# R7FA4W1AD register map
Vendor: Renesas; Series: RA4; File version: 1.0
CPU: CM4 r0p1, little endian, MPU, FPU, VTOR, 4 interrupt priority bits
Registers are 8-bit, read-write, reset 0x0 unless marked. A register's access mark holds for its fields unless they carry their own. Offsets are from the block's base; [hi:lo] are bit positions; {n}, {i} and the like mark numbered series; 'fields as' and 'values as' point back to an identical list.

## PMISC — Miscellaneous Port Control Register
Base 0x40040D00
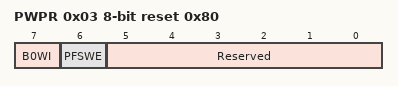
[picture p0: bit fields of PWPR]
0x03 PWPR reset 0x80 — Write-Protect Register
  [7] B0WI — PFSWE Bit Write Disable
    0=Writing to the PFSWE bit is enabled; 1=Writing to the PFSWE bit is disabled
  [6] PFSWE — PFS Register Write Enable
    0=Writing to the PFS register is disabled; 1=Writing to the PFS register is enabled
  [5:0] Reserved — These bits are read as 000000. The write value should be 000000.

## ELC — Event Link Controller
Base 0x40041000
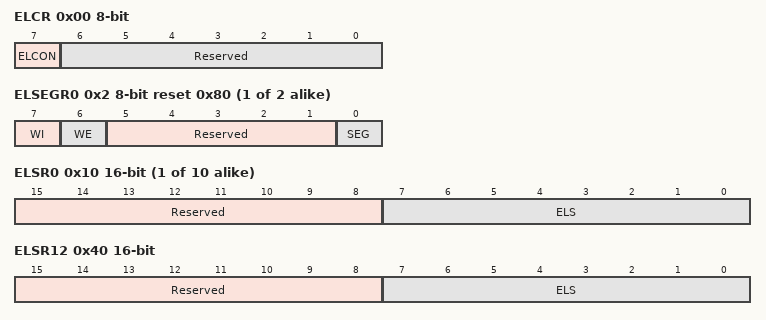
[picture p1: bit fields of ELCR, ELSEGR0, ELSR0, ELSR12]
0x00 ELCR — Event Link Controller Register
  [7] ELCON — All Event Link Enable
    0=ELC function is disabled; 1=ELC function is enabled
  [6:0] Reserved — These bits are read as 0000000. The write value should be 0000000.
{0x2+2i} ELSEGR{i} (i=0..1) reset 0x80 — Event Link Software Event Generation Register {i}
  [7] WI wo — ELSEGR Register Write Disable
    0=Write to ELSEGR register is enabled; 1=Write to ELSEGR register is disabled
  [6] WE — SEG Bit Write Enable
    0=Write to SEG bit is disabled; 1=Write to SEG bit is enabled
  [5:1] Reserved — These bits are read as 00000. The write value should be 00000.
  [0] SEG wo — Software Event Generation
    0=Normal operation; 1=Software event is generated
{0x10+4i} ELSR{i} (i=0..9) 16-bit — Event Link Setting Register {i}
  [15:8] Reserved — These bits are read as 00000000. The write value should be 00000000.
  [7:0] ELS — Event Link Select
    0=Event output to the corresponding peripheral module is disabled; other=others (Set the number for the event signal to be linked.)
0x40 ELSR12 16-bit — Event Link Setting Register 12
  fields as ELSR0
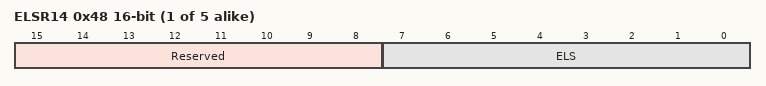
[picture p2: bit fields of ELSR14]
{0x10+4i} ELSR{i} (i=14..18) 16-bit — Event Link Setting Register {i}
  fields as ELSR0

## DOC — Data Operation Circuit
Base 0x40054100
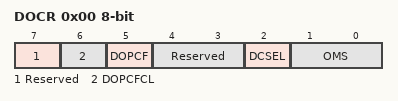
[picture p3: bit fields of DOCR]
0x00 DOCR — DOC Control Register
  [7] Reserved — This bit is read as 0. The write value should be 0.
  [6] DOPCFCL — DOPCF Clear
    0=Maintains the DOPCF flag state; 1=Clears the DOPCF flag
  [5] DOPCF ro — Data Operation Circuit FlagIndicates the result of an operation.
  [4:3] Reserved — These bits are read as 00. The write value should be 00.
  [2] DCSEL — Detection Condition Select
    0=DOPCF is set when data mismatch is detected; 1=DOPCF is set when data match is detected
  [1:0] OMS — Operating Mode Select
    0=Data comparison mode; 1=Data addition mode; 2=Data subtraction mode; 3=Setting prohibited
0x02 DODIR 16-bit — DOC Data Input Register
  [15:0] DODIR — 16-bit read-write register in which 16-bit data for use in the operations are stored.
0x04 DODSR 16-bit — DOC Data Setting Register
  [15:0] DODSR — This register stores 16-bit data for use as a reference in data comparison mode. This register also stores the results of operations in data addition and data subtraction modes.

## CRC — CRC Calculator
Base 0x40074000
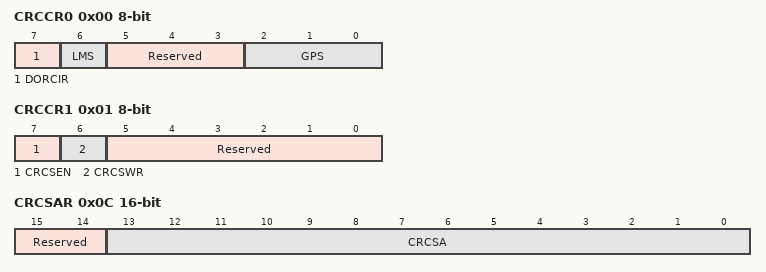
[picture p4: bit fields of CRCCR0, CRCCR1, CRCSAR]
0x00 CRCCR0 — CRC Control Register0
  [7] DORCIR wo — CRCDOR Register Clear
    0=No effect; 1=Clears the CRCDOR register
  [6] LMS — CRC Calculation Switching
    0=Generates CRC for LSB first communication; 1=Generates CRC for MSB first communication
  [5:3] Reserved — These bits are read as 000. The write value should be 000.
  [2:0] GPS — CRC Generating Polynomial Switching
    0=No calculation is executed; 1=8-bit CRC-8 (X8 + X2 + X + 1); 2=16-bit CRC-16 (X16 + X15 + X2 + 1); 3=16-bit CRC-CCITT (X16 + X12 + X5 + 1); 4=32-bit CRC-32 (X32+X26+X23+X22+X16+X12+X11+X10+X8+X7+X5+X4+X2+X+1); 5=32-bit CRC-32C (X32+X28+X27+X26+ X25+X23+X22+X20+X19+X18+X14+X13+X11+X10+X9+X8+X6+1); other=others (No calculation is executed.)
0x01 CRCCR1 — CRC Control Register1
  [7] CRCSEN — Snoop enable bit
    0=Disabled; 1=Enabled
  [6] CRCSWR — Snoop-on-write/read switch bit
    0=Snoop-on-read; 1=Snoop-on-write
  [5:0] Reserved — These bits are read as 000000. The write value should be 000000.
0x04 CRCDIR 32-bit — CRC Data Input Register
  [31:0] CRCDIR — Calculation input Data (Case of CRC-32, CRC-32C )
0x04 CRCDIR_BY (alternate view of CRCDIR) — CRC Data Input Register (byte access)
  [7:0] CRCDIR_BY — Calculation input Data ( Case of CRC-8, CRC-16 or CRC-CCITT )
0x08 CRCDOR 32-bit — CRC Data Output Register
  [31:0] CRCDOR — Calculation output Data (Case of CRC-32, CRC-32C )
0x08 CRCDOR_HA 16-bit (alternate view of CRCDOR) — CRC Data Output Register (halfword access)
  [15:0] CRCDOR_HA — Calculation output Data (Case of CRC-16 or CRC-CCITT )
0x08 CRCDOR_BY (alternate view of CRCDOR) — CRC Data Output Register(byte access)
  [7:0] CRCDOR_BY — Calculation output Data (Case of CRC-8 )
0x0C CRCSAR 16-bit — Snoop Address Register
  [15:14] Reserved — These bits are read as 00. The write value should be 00.
  [13:0] CRCSA — snoop address bitSet the I/O register address to snoop
    3=SCI0.TDR; 5=SCI0.RDR; 35=SCI1.TDR; 37=SCI1.RDR; 67=SCI2.TDR; 69=SCI2.RDR; 99=SCI3.TDR; 101=SCI3.RDR; 131=SCI4.TDR; 133=SCI4.RDR; 0x123=SCI9.TDR; 0x125=SCI9.RDR; other=others (Settings other than above are prohibited.)
